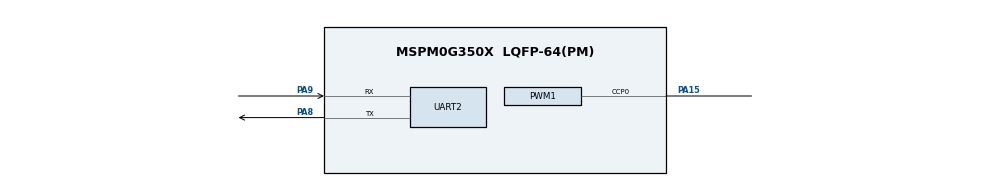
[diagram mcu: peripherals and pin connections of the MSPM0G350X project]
/**
 * @cliArgs --device "MSPM0G350X" --part "Default" --package "LQFP-64(PM)" --product "mspm0_sdk@2.09.00.00"
 * @versions {"tool":"1.26.0+4407"}
 */

/**
 * Import the modules used in this configuration.
 */
const GPIO   = scripting.addModule("/ti/driverlib/GPIO", {}, false);
const GPIO1  = GPIO.addInstance();
const GPIO2  = GPIO.addInstance();
const GPIO3  = GPIO.addInstance();
const PWM    = scripting.addModule("/ti/driverlib/PWM", {}, false);
const PWM1   = PWM.addInstance();
const SYSCTL = scripting.addModule("/ti/driverlib/SYSCTL");
const TIMER  = scripting.addModule("/ti/driverlib/TIMER", {}, false);
const TIMER1 = TIMER.addInstance();
const UART   = scripting.addModule("/ti/driverlib/UART", {}, false);
const UART1  = UART.addInstance();
const UART2  = UART.addInstance();

/**
 * Write custom configuration values to the imported modules.
 */
GPIO1.$name                          = "GPIO_LED";
GPIO1.associatedPins.create(2);
GPIO1.associatedPins[0].$name        = "LED_PIN_0";
GPIO1.associatedPins[0].assignedPort = "PORTB";
GPIO1.associatedPins[0].assignedPin  = "22";
GPIO1.associatedPins[1].$name        = "LED_CHECK";
GPIO1.associatedPins[1].assignedPort = "PORTA";
GPIO1.associatedPins[1].assignedPin  = "27";

const Board = scripting.addModule("/ti/driverlib/Board", {}, false);

GPIO2.$name                              = "GPIO_KEY";
GPIO2.associatedPins[0].$name            = "KEY_1";
GPIO2.associatedPins[0].direction        = "INPUT";
GPIO2.associatedPins[0].internalResistor = "PULL_UP";
GPIO2.associatedPins[0].assignedPort     = "PORTB";
GPIO2.associatedPins[0].assignedPin      = "21";

GPIO3.$name                          = "GPIO_OLED";
GPIO3.associatedPins.create(2);
GPIO3.associatedPins[0].$name        = "OLED_SCL";
GPIO3.associatedPins[0].initialValue = "SET";
GPIO3.associatedPins[0].assignedPort = "PORTA";
GPIO3.associatedPins[0].assignedPin  = "1";
GPIO3.associatedPins[1].$name        = "OLED_SDA";
GPIO3.associatedPins[1].initialValue = "SET";
GPIO3.associatedPins[1].assignedPort = "PORTA";
GPIO3.associatedPins[1].assignedPin  = "0";

PWM1.clockDivider                       = 8;
PWM1.timerStartTimer                    = true;
PWM1.pwmMode                            = "EDGE_ALIGN_UP";
PWM1.$name                              = "PWM_MOTOR";
PWM1.ccIndex                            = [0];
PWM1.PWM_CHANNEL_0.$name                = "ti_driverlib_pwm_PWMTimerCC0";
PWM1.ccp0PinConfig.$name                = "ti_driverlib_gpio_GPIOPinGeneric0";
PWM1.ccp0PinConfig.direction            = scripting.forceWrite("OUTPUT");
PWM1.ccp0PinConfig.hideOutputInversion  = scripting.forceWrite(false);
PWM1.ccp0PinConfig.onlyInternalResistor = scripting.forceWrite(false);
PWM1.ccp0PinConfig.passedPeripheralType = scripting.forceWrite("Digital");
PWM1.peripheral.ccp0Pin.$assign         = "PA15";

SYSCTL.forceDefaultClkConfig = true;

TIMER1.$name              = "TIMER_0";
TIMER1.interrupts         = ["ZERO"];
TIMER1.timerStartTimer    = true;
TIMER1.timerMode          = "PERIODIC";
TIMER1.timerPeriod        = "1 ms";
TIMER1.peripheral.$assign = "TIMG0";

UART1.$name                                = "UART_0";
UART1.targetBaudRate                       = 115200;
UART1.enableFIFO                           = true;
UART1.rxFifoThreshold                      = "DL_UART_RX_FIFO_LEVEL_ONE_ENTRY";
UART1.enabledDMARXTriggers                 = "DL_UART_DMA_INTERRUPT_RX";
UART1.txFifoThreshold                      = "DL_UART_TX_FIFO_LEVEL_ONE_ENTRY";
UART1.enabledInterrupts                    = ["DMA_DONE_RX","DMA_DONE_TX"];
UART1.enabledDMATXTriggers                 = "DL_UART_DMA_INTERRUPT_TX";
UART1.peripheral.$assign                   = "UART0";
UART1.txPinConfig.$name                    = "ti_driverlib_gpio_GPIOPinGeneric1";
UART1.rxPinConfig.$name                    = "ti_driverlib_gpio_GPIOPinGeneric2";
UART1.DMA_CHANNEL_RX.$name                 = "DMA_CH0";
UART1.DMA_CHANNEL_RX.srcLength             = "BYTE";
UART1.DMA_CHANNEL_RX.dstLength             = "BYTE";
UART1.DMA_CHANNEL_RX.configureTransferSize = true;
UART1.DMA_CHANNEL_RX.transferMode          = "FULL_CH_REPEAT_SINGLE";
UART1.DMA_CHANNEL_TX.$name                 = "DMA_CH2";
UART1.DMA_CHANNEL_TX.srcLength             = "BYTE";
UART1.DMA_CHANNEL_TX.dstLength             = "BYTE";
UART1.DMA_CHANNEL_TX.addressMode           = "b2f";

UART2.$name                                = "UART_1";
UART2.targetBaudRate                       = 115200;
UART2.enableFIFO                           = true;
UART2.rxFifoThreshold                      = "DL_UART_RX_FIFO_LEVEL_ONE_ENTRY";
UART2.enabledInterrupts                    = ["DMA_DONE_RX"];
UART2.enabledDMARXTriggers                 = "DL_UART_DMA_INTERRUPT_RX";
UART2.peripheral.$assign                   = "UART1";
UART2.peripheral.rxPin.$assign             = "PA9";
UART2.peripheral.txPin.$assign             = "PA8";
UART2.txPinConfig.$name                    = "ti_driverlib_gpio_GPIOPinGeneric3";
UART2.rxPinConfig.$name                    = "ti_driverlib_gpio_GPIOPinGeneric4";
UART2.DMA_CHANNEL_RX.$name                 = "DMA_CH1";
UART2.DMA_CHANNEL_RX.srcLength             = "BYTE";
UART2.DMA_CHANNEL_RX.dstLength             = "BYTE";
UART2.DMA_CHANNEL_RX.configureTransferSize = true;
UART2.DMA_CHANNEL_RX.transferMode          = "FULL_CH_REPEAT_SINGLE";

/**
 * Pinmux solution for unlocked pins/peripherals. This ensures that minor changes to the automatic solver in a future
 * version of the tool will not impact the pinmux you originally saw.  These lines can be completely deleted in order to
 * re-solve from scratch.
 */
GPIO1.associatedPins[0].pin.$suggestSolution     = "PB22";
GPIO1.associatedPins[1].pin.$suggestSolution     = "PA27";
Board.peripheral.$suggestSolution                = "DEBUGSS";
Board.peripheral.swclkPin.$suggestSolution       = "PA20";
Board.peripheral.swdioPin.$suggestSolution       = "PA19";
GPIO2.associatedPins[0].pin.$suggestSolution     = "PB21";
GPIO3.associatedPins[0].pin.$suggestSolution     = "PA1";
GPIO3.associatedPins[1].pin.$suggestSolution     = "PA0";
PWM1.peripheral.$suggestSolution                 = "TIMA1";
SYSCTL.peripheral.$suggestSolution               = "SYSCTL";
UART1.peripheral.rxPin.$suggestSolution          = "PA11";
UART1.peripheral.txPin.$suggestSolution          = "PA10";
UART1.DMA_CHANNEL_RX.peripheral.$suggestSolution = "DMA_CH2";
UART1.DMA_CHANNEL_TX.peripheral.$suggestSolution = "DMA_CH1";
UART2.DMA_CHANNEL_RX.peripheral.$suggestSolution = "DMA_CH0";
